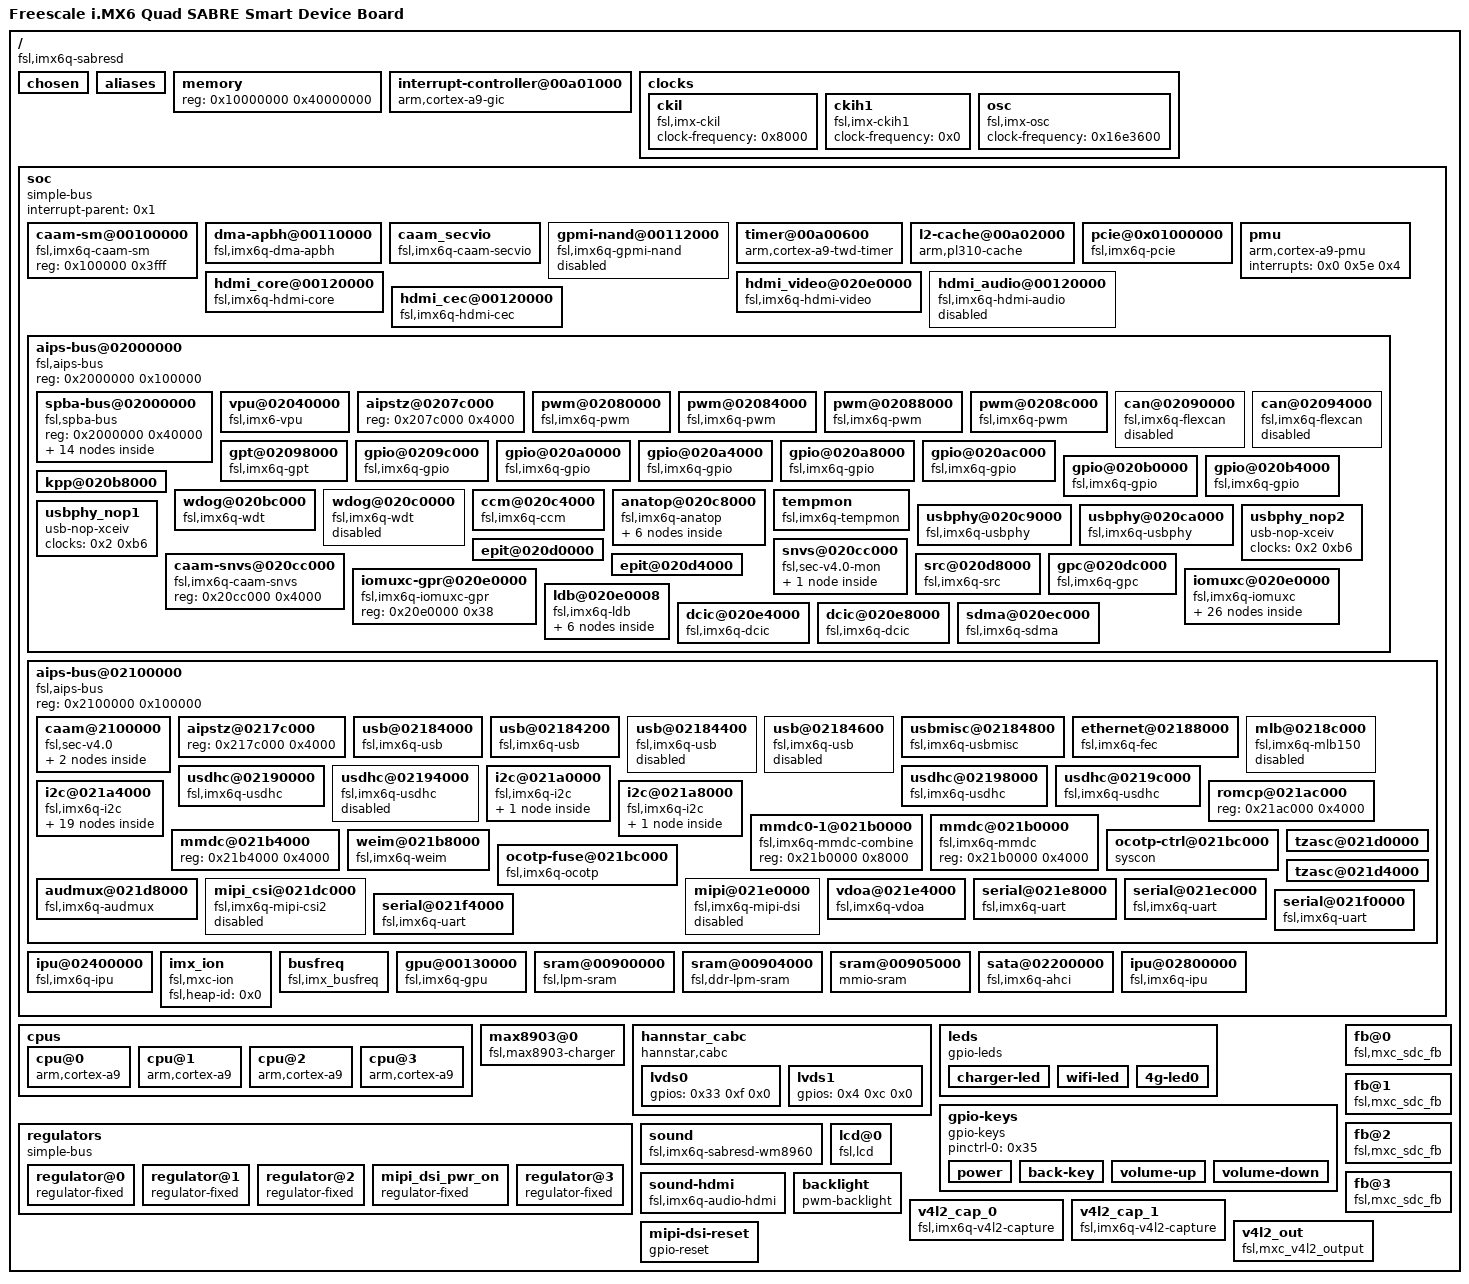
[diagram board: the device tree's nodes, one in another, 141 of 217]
/dts-v1/;

/ {
	#address-cells = <0x1>;
	#size-cells = <0x1>;
	model = "Freescale i.MX6 Quad SABRE Smart Device Board";
	compatible = "fsl,imx6q-sabresd", "fsl,imx6q";

	chosen {
	};

	aliases {
		gpio0 = "/soc/aips-bus@02000000/gpio@0209c000";
		gpio1 = "/soc/aips-bus@02000000/gpio@020a0000";
		gpio2 = "/soc/aips-bus@02000000/gpio@020a4000";
		gpio3 = "/soc/aips-bus@02000000/gpio@020a8000";
		gpio4 = "/soc/aips-bus@02000000/gpio@020ac000";
		gpio5 = "/soc/aips-bus@02000000/gpio@020b0000";
		gpio6 = "/soc/aips-bus@02000000/gpio@020b4000";
		i2c0 = "/soc/aips-bus@02100000/i2c@021a0000";
		i2c1 = "/soc/aips-bus@02100000/i2c@021a4000";
		i2c2 = "/soc/aips-bus@02100000/i2c@021a8000";
		ipu0 = "/soc/ipu@02400000";
		mmc0 = "/soc/aips-bus@02100000/usdhc@02190000";
		mmc1 = "/soc/aips-bus@02100000/usdhc@02194000";
		mmc2 = "/soc/aips-bus@02100000/usdhc@02198000";
		mmc3 = "/soc/aips-bus@02100000/usdhc@0219c000";
		serial0 = "/soc/aips-bus@02000000/spba-bus@02000000/serial@02020000";
		serial1 = "/soc/aips-bus@02100000/serial@021e8000";
		serial2 = "/soc/aips-bus@02100000/serial@021ec000";
		serial3 = "/soc/aips-bus@02100000/serial@021f0000";
		serial4 = "/soc/aips-bus@02100000/serial@021f4000";
		spi0 = "/soc/aips-bus@02000000/spba-bus@02000000/ecspi@02008000";
		spi1 = "/soc/aips-bus@02000000/spba-bus@02000000/ecspi@0200c000";
		spi2 = "/soc/aips-bus@02000000/spba-bus@02000000/ecspi@02010000";
		spi3 = "/soc/aips-bus@02000000/spba-bus@02000000/ecspi@02014000";
		usbphy0 = "/soc/aips-bus@02000000/usbphy@020c9000";
		usbphy1 = "/soc/aips-bus@02000000/usbphy@020ca000";
		ipu1 = "/soc/ipu@02800000";
		mxcfb0 = "/fb@0";
		mxcfb1 = "/fb@1";
		mxcfb2 = "/fb@2";
		mxcfb3 = "/fb@3";
	};

	memory {
		device_type = "memory";
		reg = <0x10000000 0x40000000>;
	};

	interrupt-controller@00a01000 {
		compatible = "arm,cortex-a9-gic";
		#interrupt-cells = <0x3>;
		#address-cells = <0x1>;
		#size-cells = <0x1>;
		interrupt-controller;
		reg = <0xa01000 0x1000 0xa00100 0x100>;
		linux,phandle = <0x1>;
		phandle = <0x1>;
	};

	clocks {
		#address-cells = <0x1>;
		#size-cells = <0x0>;

		ckil {
			compatible = "fsl,imx-ckil", "fixed-clock";
			clock-frequency = <0x8000>;
		};

		ckih1 {
			compatible = "fsl,imx-ckih1", "fixed-clock";
			clock-frequency = <0x0>;
		};

		osc {
			compatible = "fsl,imx-osc", "fixed-clock";
			clock-frequency = <0x16e3600>;
		};
	};

	soc {
		#address-cells = <0x1>;
		#size-cells = <0x1>;
		compatible = "simple-bus";
		interrupt-parent = <0x1>;
		ranges;

		caam-sm@00100000 {
			compatible = "fsl,imx6q-caam-sm";
			reg = <0x100000 0x3fff>;
		};

		dma-apbh@00110000 {
			compatible = "fsl,imx6q-dma-apbh", "fsl,imx28-dma-apbh";
			reg = <0x110000 0x2000>;
			interrupts = <0x0 0xd 0x4 0x0 0xd 0x4 0x0 0xd 0x4 0x0 0xd 0x4>;
			interrupt-names = "gpmi0", "gpmi1", "gpmi2", "gpmi3";
			#dma-cells = <0x1>;
			dma-channels = <0x4>;
			clocks = <0x2 0x6a>;
			linux,phandle = <0x3>;
			phandle = <0x3>;
		};

		caam_secvio {
			compatible = "fsl,imx6q-caam-secvio";
			interrupts = <0x0 0x14 0x4>;
			secvio_src = <0x8000001d>;
		};

		gpmi-nand@00112000 {
			compatible = "fsl,imx6q-gpmi-nand";
			#address-cells = <0x1>;
			#size-cells = <0x1>;
			reg = <0x112000 0x2000 0x114000 0x2000>;
			reg-names = "gpmi-nand", "bch";
			interrupts = <0x0 0xf 0x4>;
			interrupt-names = "bch";
			clocks = <0x2 0x98 0x2 0x99 0x2 0x97 0x2 0x96 0x2 0x95>;
			clock-names = "gpmi_io", "gpmi_apb", "gpmi_bch", "gpmi_bch_apb", "per1_bch";
			dmas = <0x3 0x0>;
			dma-names = "rx-tx";
			status = "disabled";
		};

		timer@00a00600 {
			compatible = "arm,cortex-a9-twd-timer";
			reg = <0xa00600 0x20>;
			interrupts = <0x1 0xd 0xf01>;
			clocks = <0x2 0xf>;
		};

		l2-cache@00a02000 {
			compatible = "arm,pl310-cache";
			reg = <0xa02000 0x1000>;
			interrupts = <0x0 0x5c 0x4>;
			cache-unified;
			cache-level = <0x2>;
			arm,tag-latency = <0x4 0x2 0x3>;
			arm,data-latency = <0x4 0x2 0x3>;
			linux,phandle = <0x30>;
			phandle = <0x30>;
		};

		pcie@0x01000000 {
			compatible = "fsl,imx6q-pcie", "snps,dw-pcie";
			reg = <0x1ffc000 0x4000 0x1f00000 0x80000>;
			reg-names = "dbi", "config";
			#address-cells = <0x3>;
			#size-cells = <0x2>;
			device_type = "pci";
			ranges = <0x81000000 0x0 0x0 0x1f80000 0x0 0x10000 0x82000000 0x0 0x1000000 0x1000000 0x0 0xf00000>;
			num-lanes = <0x1>;
			interrupts = <0x0 0x78 0x4>;
			interrupt-names = "msi";
			#interrupt-cells = <0x1>;
			interrupt-map-mask = <0x0 0x0 0x0 0x7>;
			interrupt-map = <0x0 0x0 0x0 0x1 0x1 0x0 0x7b 0x4 0x0 0x0 0x0 0x2 0x1 0x0 0x7a 0x4 0x0 0x0 0x0 0x3 0x1 0x0 0x79 0x4 0x0 0x0 0x0 0x4 0x1 0x0 0x78 0x4>;
			clocks = <0x2 0xbd 0x2 0xbb 0x2 0xce 0x2 0x90>;
			clock-names = "pcie_phy", "ref_100m", "pcie_bus", "pcie";
			status = "okay";
			power-on-gpio = <0x4 0x4 0x0>;
			reset-gpio = <0x4 0xc 0x0>;
		};

		pmu {
			compatible = "arm,cortex-a9-pmu";
			interrupts = <0x0 0x5e 0x4>;
		};

		hdmi_core@00120000 {
			compatible = "fsl,imx6q-hdmi-core";
			reg = <0x120000 0x9000>;
			clocks = <0x2 0x7c 0x2 0x7b 0x2 0x8a>;
			clock-names = "hdmi_isfr", "hdmi_iahb", "mipi_core";
			status = "okay";
			ipu_id = <0x0>;
			disp_id = <0x1>;
		};

		hdmi_video@020e0000 {
			compatible = "fsl,imx6q-hdmi-video";
			reg = <0x20e0000 0x1000>;
			reg-names = "hdmi_gpr";
			interrupts = <0x0 0x73 0x4>;
			clocks = <0x2 0x7c 0x2 0x7b 0x2 0x8a>;
			clock-names = "hdmi_isfr", "hdmi_iahb", "mipi_core";
			status = "okay";
			fsl,phy_reg_vlev = <0x294>;
			fsl,phy_reg_cksymtx = <0x800d>;
		};

		hdmi_audio@00120000 {
			compatible = "fsl,imx6q-hdmi-audio";
			clocks = <0x2 0x7c 0x2 0x7b 0x2 0x8a>;
			clock-names = "hdmi_isfr", "hdmi_iahb", "mipi_core";
			dmas = <0x5 0x2 0x18 0x0>;
			dma-names = "tx";
			status = "disabled";
			linux,phandle = <0x38>;
			phandle = <0x38>;
		};

		hdmi_cec@00120000 {
			compatible = "fsl,imx6q-hdmi-cec";
			interrupts = <0x0 0x73 0x4>;
			status = "okay";
			pinctrl-names = "default";
			pinctrl-0 = <0x6>;
		};

		aips-bus@02000000 {
			compatible = "fsl,aips-bus", "simple-bus";
			#address-cells = <0x1>;
			#size-cells = <0x1>;
			reg = <0x2000000 0x100000>;
			ranges;

			spba-bus@02000000 {
				compatible = "fsl,spba-bus", "simple-bus";
				#address-cells = <0x1>;
				#size-cells = <0x1>;
				reg = <0x2000000 0x40000>;
				ranges;

				spdif@02004000 {
					compatible = "fsl,imx35-spdif";
					reg = <0x2004000 0x4000>;
					interrupts = <0x0 0x34 0x4>;
					dmas = <0x5 0xe 0x12 0x0 0x5 0xf 0x12 0x0>;
					dma-names = "rx", "tx";
					clocks = <0x2 0xf9 0x2 0x3 0x2 0xc5 0x2 0x6b 0x2 0x0 0x2 0x76 0x2 0x3e 0x2 0x8b 0x2 0x0 0x2 0x9c>;
					clock-names = "core", "rxtx0", "rxtx1", "rxtx2", "rxtx3", "rxtx4", "rxtx5", "rxtx6", "rxtx7", "dma";
					status = "disabled";
				};

				ecspi@02008000 {
					#address-cells = <0x1>;
					#size-cells = <0x0>;
					compatible = "fsl,imx6q-ecspi", "fsl,imx51-ecspi";
					reg = <0x2008000 0x4000>;
					interrupts = <0x0 0x1f 0x4>;
					clocks = <0x2 0x70 0x2 0x70>;
					clock-names = "ipg", "per";
					status = "okay";
					dmas = <0x5 0x3 0x7 0x1 0x5 0x4 0x7 0x2>;
					dma-names = "rx", "tx";
					fsl,spi-num-chipselects = <0x1>;
					cs-gpios = <0x7 0x9 0x0>;
					pinctrl-names = "default";
					pinctrl-0 = <0x8>;

					m25p80@0 {
						#address-cells = <0x1>;
						#size-cells = <0x1>;
						compatible = "st,m25p32";
						spi-max-frequency = <0x1312d00>;
						reg = <0x0>;
					};
				};

				ecspi@0200c000 {
					#address-cells = <0x1>;
					#size-cells = <0x0>;
					compatible = "fsl,imx6q-ecspi", "fsl,imx51-ecspi";
					reg = <0x200c000 0x4000>;
					interrupts = <0x0 0x20 0x4>;
					clocks = <0x2 0x71 0x2 0x71>;
					clock-names = "ipg", "per";
					status = "disabled";
					dmas = <0x5 0x5 0x7 0x1 0x5 0x6 0x7 0x2>;
					dma-names = "rx", "tx";
				};

				ecspi@02010000 {
					#address-cells = <0x1>;
					#size-cells = <0x0>;
					compatible = "fsl,imx6q-ecspi", "fsl,imx51-ecspi";
					reg = <0x2010000 0x4000>;
					interrupts = <0x0 0x21 0x4>;
					clocks = <0x2 0x72 0x2 0x72>;
					clock-names = "ipg", "per";
					status = "disabled";
					dmas = <0x5 0x7 0x7 0x1 0x5 0x8 0x7 0x2>;
					dma-names = "rx", "tx";
				};

				ecspi@02014000 {
					#address-cells = <0x1>;
					#size-cells = <0x0>;
					compatible = "fsl,imx6q-ecspi", "fsl,imx51-ecspi";
					reg = <0x2014000 0x4000>;
					interrupts = <0x0 0x22 0x4>;
					clocks = <0x2 0x73 0x2 0x73>;
					clock-names = "ipg", "per";
					status = "disabled";
					dmas = <0x5 0x9 0x7 0x1 0x5 0xa 0x7 0x2>;
					dma-names = "rx", "tx";
				};

				serial@02020000 {
					compatible = "fsl,imx6q-uart", "fsl,imx21-uart";
					reg = <0x2020000 0x4000>;
					interrupts = <0x0 0x1a 0x4>;
					clocks = <0x2 0xa0 0x2 0xa1>;
					clock-names = "ipg", "per";
					dmas = <0x5 0x19 0x4 0x0 0x5 0x1a 0x4 0x0>;
					dma-names = "rx", "tx";
					status = "okay";
					pinctrl-names = "default";
					pinctrl-0 = <0x9>;
				};

				esai@02024000 {
					compatible = "fsl,imx35-esai";
					reg = <0x2024000 0x4000>;
					interrupts = <0x0 0x33 0x4>;
					clocks = <0x2 0xd9 0x2 0xd0 0x2 0x76 0x2 0xd9 0x2 0x9c>;
					clock-names = "core", "mem", "extal", "fsys", "dma";
					dmas = <0x5 0x17 0x15 0x0 0x5 0x18 0x15 0x0>;
					dma-names = "rx", "tx";
					status = "disabled";
				};

				ssi@02028000 {
					compatible = "fsl,imx6q-ssi", "fsl,imx21-ssi";
					reg = <0x2028000 0x4000>;
					interrupts = <0x0 0x2e 0x4>;
					clocks = <0x2 0xb2 0x2 0x9d>;
					clock-names = "ipg", "baud";
					dmas = <0x5 0x25 0x16 0x0 0x5 0x26 0x16 0x0>;
					dma-names = "rx", "tx";
					fsl,fifo-depth = <0xf>;
					fsl,ssi-dma-events = <0x26 0x25>;
					status = "disabled";
				};

				ssi@0202c000 {
					compatible = "fsl,imx6q-ssi", "fsl,imx21-ssi";
					reg = <0x202c000 0x4000>;
					interrupts = <0x0 0x2f 0x4>;
					clocks = <0x2 0xb3 0x2 0x9e>;
					clock-names = "ipg", "baud";
					dmas = <0x5 0x29 0x16 0x0 0x5 0x2a 0x16 0x0>;
					dma-names = "rx", "tx";
					fsl,fifo-depth = <0xf>;
					fsl,ssi-dma-events = <0x2a 0x29>;
					status = "okay";
					fsl,mode = "i2s-slave";
					linux,phandle = <0x36>;
					phandle = <0x36>;
				};

				ssi@02030000 {
					compatible = "fsl,imx6q-ssi", "fsl,imx21-ssi";
					reg = <0x2030000 0x4000>;
					interrupts = <0x0 0x30 0x4>;
					clocks = <0x2 0xb4 0x2 0x9f>;
					clock-names = "ipg", "baud";
					dmas = <0x5 0x2d 0x16 0x0 0x5 0x2e 0x16 0x0>;
					dma-names = "rx", "tx";
					fsl,fifo-depth = <0xf>;
					fsl,ssi-dma-events = <0x2e 0x2d>;
					status = "disabled";
				};

				asrc@02034000 {
					compatible = "fsl,imx53-asrc";
					reg = <0x2034000 0x4000>;
					interrupts = <0x0 0x32 0x4>;
					clocks = <0x2 0xda 0x2 0xdb 0x2 0x0 0x2 0x0 0x2 0x0 0x2 0x0 0x2 0x0 0x2 0x0 0x2 0x0 0x2 0x0 0x2 0x0 0x2 0x0 0x2 0x0 0x2 0x0 0x2 0x0 0x2 0x6b 0x2 0x0 0x2 0x0 0x2 0x9c>;
					clock-names = "mem", "ipg", "asrck_0", "asrck_1", "asrck_2", "asrck_3", "asrck_4", "asrck_5", "asrck_6", "asrck_7", "asrck_8", "asrck_9", "asrck_a", "asrck_b", "asrck_c", "asrck_d", "asrck_e", "asrck_f", "dma";
					dmas = <0x5 0x11 0x17 0x1 0x5 0x12 0x17 0x1 0x5 0x13 0x17 0x1 0x5 0x14 0x17 0x1 0x5 0x15 0x17 0x1 0x5 0x16 0x17 0x1>;
					dma-names = "rxa", "rxb", "rxc", "txa", "txb", "txc";
					fsl,asrc-rate = <0xbb80>;
					fsl,asrc-width = <0x10>;
					status = "okay";
				};

				spba@0203c000 {
					reg = <0x203c000 0x4000>;
				};

				ecspi@02018000 {
					#address-cells = <0x1>;
					#size-cells = <0x0>;
					compatible = "fsl,imx6q-ecspi", "fsl,imx51-ecspi";
					reg = <0x2018000 0x4000>;
					interrupts = <0x0 0x23 0x4>;
					clocks = <0x2 0x74 0x2 0x74>;
					clock-names = "ipg", "per";
					status = "disabled";
				};
			};

			vpu@02040000 {
				compatible = "fsl,imx6-vpu";
				reg = <0x2040000 0x3c000>;
				reg-names = "vpu_regs";
				interrupts = <0x0 0x3 0x1 0x0 0xc 0x4>;
				interrupt-names = "vpu_jpu_irq", "vpu_ipi_irq";
				clocks = <0x2 0xa8 0x2 0x8c 0x2 0x8e>;
				clock-names = "vpu_clk", "mmdc_ch0_axi", "ocram";
				iramsize = <0x21000>;
				iram = <0xa>;
				resets = <0xb 0x1>;
				power-domains = <0xc 0x1>;
			};

			aipstz@0207c000 {
				reg = <0x207c000 0x4000>;
			};

			pwm@02080000 {
				#pwm-cells = <0x2>;
				compatible = "fsl,imx6q-pwm", "fsl,imx27-pwm";
				reg = <0x2080000 0x4000>;
				interrupts = <0x0 0x53 0x4>;
				clocks = <0x2 0x3e 0x2 0x91>;
				clock-names = "ipg", "per";
				pinctrl-names = "default";
				pinctrl-0 = <0xd>;
				status = "okay";
				linux,phandle = <0x3a>;
				phandle = <0x3a>;
			};

			pwm@02084000 {
				#pwm-cells = <0x2>;
				compatible = "fsl,imx6q-pwm", "fsl,imx27-pwm";
				reg = <0x2084000 0x4000>;
				interrupts = <0x0 0x54 0x4>;
				clocks = <0x2 0x3e 0x2 0x92>;
				clock-names = "ipg", "per";
			};

			pwm@02088000 {
				#pwm-cells = <0x2>;
				compatible = "fsl,imx6q-pwm", "fsl,imx27-pwm";
				reg = <0x2088000 0x4000>;
				interrupts = <0x0 0x55 0x4>;
				clocks = <0x2 0x3e 0x2 0x93>;
				clock-names = "ipg", "per";
			};

			pwm@0208c000 {
				#pwm-cells = <0x2>;
				compatible = "fsl,imx6q-pwm", "fsl,imx27-pwm";
				reg = <0x208c000 0x4000>;
				interrupts = <0x0 0x56 0x4>;
				clocks = <0x2 0x3e 0x2 0x94>;
				clock-names = "ipg", "per";
			};

			can@02090000 {
				compatible = "fsl,imx6q-flexcan";
				reg = <0x2090000 0x4000>;
				interrupts = <0x0 0x6e 0x4>;
				clocks = <0x2 0x6c 0x2 0x6d>;
				clock-names = "ipg", "per";
				stop-mode = <0xe 0x34 0x1c 0x10 0x11>;
				status = "disabled";
			};

			can@02094000 {
				compatible = "fsl,imx6q-flexcan";
				reg = <0x2094000 0x4000>;
				interrupts = <0x0 0x6f 0x4>;
				clocks = <0x2 0x6e 0x2 0x6f>;
				clock-names = "ipg", "per";
				stop-mode = <0xe 0x34 0x1d 0x10 0x12>;
				status = "disabled";
			};

			gpt@02098000 {
				compatible = "fsl,imx6q-gpt", "fsl,imx31-gpt";
				reg = <0x2098000 0x4000>;
				interrupts = <0x0 0x37 0x4>;
				clocks = <0x2 0x77 0x2 0x78>;
				clock-names = "ipg", "per";
			};

			gpio@0209c000 {
				compatible = "fsl,imx6q-gpio", "fsl,imx35-gpio";
				reg = <0x209c000 0x4000>;
				interrupts = <0x0 0x42 0x4 0x0 0x43 0x4>;
				gpio-controller;
				#gpio-cells = <0x2>;
				interrupt-controller;
				#interrupt-cells = <0x2>;
				linux,phandle = <0x34>;
				phandle = <0x34>;
			};

			gpio@020a0000 {
				compatible = "fsl,imx6q-gpio", "fsl,imx35-gpio";
				reg = <0x20a0000 0x4000>;
				interrupts = <0x0 0x44 0x4 0x0 0x45 0x4>;
				gpio-controller;
				#gpio-cells = <0x2>;
				interrupt-controller;
				#interrupt-cells = <0x2>;
				linux,phandle = <0x22>;
				phandle = <0x22>;
			};

			gpio@020a4000 {
				compatible = "fsl,imx6q-gpio", "fsl,imx35-gpio";
				reg = <0x20a4000 0x4000>;
				interrupts = <0x0 0x46 0x4 0x0 0x47 0x4>;
				gpio-controller;
				#gpio-cells = <0x2>;
				interrupt-controller;
				#interrupt-cells = <0x2>;
				linux,phandle = <0x27>;
				phandle = <0x27>;
			};

			gpio@020a8000 {
				compatible = "fsl,imx6q-gpio", "fsl,imx35-gpio";
				reg = <0x20a8000 0x4000>;
				interrupts = <0x0 0x48 0x4 0x0 0x49 0x4>;
				gpio-controller;
				#gpio-cells = <0x2>;
				interrupt-controller;
				#interrupt-cells = <0x2>;
				linux,phandle = <0x7>;
				phandle = <0x7>;
			};

			gpio@020ac000 {
				compatible = "fsl,imx6q-gpio", "fsl,imx35-gpio";
				reg = <0x20ac000 0x4000>;
				interrupts = <0x0 0x4a 0x4 0x0 0x4b 0x4>;
				gpio-controller;
				#gpio-cells = <0x2>;
				interrupt-controller;
				#interrupt-cells = <0x2>;
				linux,phandle = <0x1f>;
				phandle = <0x1f>;
			};

			gpio@020b0000 {
				compatible = "fsl,imx6q-gpio", "fsl,imx35-gpio";
				reg = <0x20b0000 0x4000>;
				interrupts = <0x0 0x4c 0x4 0x0 0x4d 0x4>;
				gpio-controller;
				#gpio-cells = <0x2>;
				interrupt-controller;
				#interrupt-cells = <0x2>;
				linux,phandle = <0x33>;
				phandle = <0x33>;
			};

			gpio@020b4000 {
				compatible = "fsl,imx6q-gpio", "fsl,imx35-gpio";
				reg = <0x20b4000 0x4000>;
				interrupts = <0x0 0x4e 0x4 0x0 0x4f 0x4>;
				gpio-controller;
				#gpio-cells = <0x2>;
				interrupt-controller;
				#interrupt-cells = <0x2>;
				linux,phandle = <0x4>;
				phandle = <0x4>;
			};

			kpp@020b8000 {
				reg = <0x20b8000 0x4000>;
				interrupts = <0x0 0x52 0x4>;
			};

			wdog@020bc000 {
				compatible = "fsl,imx6q-wdt", "fsl,imx21-wdt";
				reg = <0x20bc000 0x4000>;
				interrupts = <0x0 0x50 0x4>;
				clocks = <0x2 0x0>;
				status = "okay";
			};

			wdog@020c0000 {
				compatible = "fsl,imx6q-wdt", "fsl,imx21-wdt";
				reg = <0x20c0000 0x4000>;
				interrupts = <0x0 0x51 0x4>;
				clocks = <0x2 0x0>;
				status = "disabled";
			};

			ccm@020c4000 {
				compatible = "fsl,imx6q-ccm";
				reg = <0x20c4000 0x4000>;
				interrupts = <0x0 0x57 0x4 0x0 0x58 0x4>;
				#clock-cells = <0x1>;
				fsl,ldb-di0-parent = <0x2 0x4>;
				fsl,ldb-di1-parent = <0x2 0x4>;
				linux,phandle = <0x2>;
				phandle = <0x2>;
			};

			anatop@020c8000 {
				compatible = "fsl,imx6q-anatop", "syscon", "simple-bus";
				reg = <0x20c8000 0x1000>;
				interrupts = <0x0 0x31 0x4 0x0 0x36 0x4 0x0 0x7f 0x4>;
				linux,phandle = <0xf>;
				phandle = <0xf>;

				regulator-1p1@110 {
					compatible = "fsl,anatop-regulator";
					regulator-name = "vdd1p1";
					regulator-min-microvolt = <0xc3500>;
					regulator-max-microvolt = <0x14fb18>;
					regulator-always-on;
					anatop-reg-offset = <0x110>;
					anatop-vol-bit-shift = <0x8>;
					anatop-vol-bit-width = <0x5>;
					anatop-min-bit-val = <0x4>;
					anatop-min-voltage = <0xc3500>;
					anatop-max-voltage = <0x14fb18>;
					anatop-enable-bit = <0x0>;
				};

				regulator-3p0@120 {
					compatible = "fsl,anatop-regulator";
					regulator-name = "vdd3p0";
					regulator-min-microvolt = <0x280de8>;
					regulator-max-microvolt = <0x33e140>;
					anatop-reg-offset = <0x120>;
					anatop-vol-bit-shift = <0x8>;
					anatop-vol-bit-width = <0x5>;
					anatop-min-bit-val = <0x0>;
					anatop-min-voltage = <0x280de8>;
					anatop-max-voltage = <0x33e140>;
					anatop-enable-bit = <0x0>;
					linux,phandle = <0x11>;
					phandle = <0x11>;
				};

				regulator-2p5@130 {
					compatible = "fsl,anatop-regulator";
					regulator-name = "vdd2p5";
					regulator-min-microvolt = <0x1e8480>;
					regulator-max-microvolt = <0x29f630>;
					regulator-always-on;
					anatop-reg-offset = <0x130>;
					anatop-vol-bit-shift = <0x8>;
					anatop-vol-bit-width = <0x5>;
					anatop-min-bit-val = <0x0>;
					anatop-min-voltage = <0x1e8480>;
					anatop-max-voltage = <0x29f630>;
					anatop-enable-bit = <0x0>;
				};

				regulator-vddcore@140 {
					compatible = "fsl,anatop-regulator";
					regulator-name = "vddarm";
					regulator-min-microvolt = <0xb1008>;
					regulator-max-microvolt = <0x162010>;
					regulator-always-on;
					anatop-reg-offset = <0x140>;
					anatop-vol-bit-shift = <0x0>;
					anatop-vol-bit-width = <0x5>;
					anatop-delay-reg-offset = <0x170>;
					anatop-delay-bit-shift = <0x18>;
					anatop-delay-bit-width = <0x2>;
					anatop-min-bit-val = <0x1>;
					anatop-min-voltage = <0xb1008>;
					anatop-max-voltage = <0x162010>;
					regulator-allow-bypass;
					linux,phandle = <0x31>;
					phandle = <0x31>;
				};

				regulator-vddpu@140 {
					compatible = "fsl,anatop-regulator";
					regulator-name = "vddpu";
					regulator-min-microvolt = <0xb1008>;
					regulator-max-microvolt = <0x162010>;
					regulator-enable-ramp-delay = <0x96>;
					regulator-boot-on;
					anatop-reg-offset = <0x140>;
					anatop-vol-bit-shift = <0x9>;
					anatop-vol-bit-width = <0x5>;
					anatop-delay-reg-offset = <0x170>;
					anatop-delay-bit-shift = <0x1a>;
					anatop-delay-bit-width = <0x2>;
					anatop-min-bit-val = <0x1>;
					anatop-min-voltage = <0xb1008>;
					anatop-max-voltage = <0x162010>;
					regulator-allow-bypass;
					linux,phandle = <0x12>;
					phandle = <0x12>;
				};

				regulator-vddsoc@140 {
					compatible = "fsl,anatop-regulator";
					regulator-name = "vddsoc";
					regulator-min-microvolt = <0xb1008>;
					regulator-max-microvolt = <0x162010>;
					regulator-always-on;
					anatop-reg-offset = <0x140>;
					anatop-vol-bit-shift = <0x12>;
					anatop-vol-bit-width = <0x5>;
					anatop-delay-reg-offset = <0x170>;
					anatop-delay-bit-shift = <0x1c>;
					anatop-delay-bit-width = <0x2>;
					anatop-min-bit-val = <0x1>;
					anatop-min-voltage = <0xb1008>;
					anatop-max-voltage = <0x162010>;
					regulator-allow-bypass;
					linux,phandle = <0x32>;
					phandle = <0x32>;
				};
			};

			tempmon {
				compatible = "fsl,imx6q-tempmon";
				interrupts = <0x0 0x31 0x4>;
				fsl,tempmon = <0xf>;
				fsl,tempmon-data = <0x10>;
				clocks = <0x2 0xac>;
			};

			usbphy@020c9000 {
				compatible = "fsl,imx6q-usbphy", "fsl,imx23-usbphy";
				reg = <0x20c9000 0x1000>;
				interrupts = <0x0 0x2c 0x4>;
				clocks = <0x2 0xb6>;
				phy-3p0-supply = <0x11>;
				fsl,anatop = <0xf>;
				linux,phandle = <0x16>;
				phandle = <0x16>;
			};

			usbphy@020ca000 {
				compatible = "fsl,imx6q-usbphy", "fsl,imx23-usbphy";
				reg = <0x20ca000 0x1000>;
				interrupts = <0x0 0x2d 0x4>;
				clocks = <0x2 0xb7>;
				phy-3p0-supply = <0x11>;
				fsl,anatop = <0xf>;
				linux,phandle = <0x1a>;
				phandle = <0x1a>;
			};

			usbphy_nop1 {
				compatible = "usb-nop-xceiv";
				clocks = <0x2 0xb6>;
				clock-names = "main_clk";
				linux,phandle = <0x1c>;
				phandle = <0x1c>;
			};

			usbphy_nop2 {
				compatible = "usb-nop-xceiv";
				clocks = <0x2 0xb6>;
				clock-names = "main_clk";
				linux,phandle = <0x1d>;
				phandle = <0x1d>;
			};

			caam-snvs@020cc000 {
				compatible = "fsl,imx6q-caam-snvs";
				reg = <0x20cc000 0x4000>;
			};

			snvs@020cc000 {
				compatible = "fsl,sec-v4.0-mon", "simple-bus";
				#address-cells = <0x1>;
				#size-cells = <0x1>;
				ranges = <0x0 0x20cc000 0x4000>;

				snvs-rtc-lp@34 {
					compatible = "fsl,sec-v4.0-mon-rtc-lp";
					reg = <0x34 0x58>;
					interrupts = <0x0 0x13 0x4 0x0 0x14 0x4>;
				};
			};

			epit@020d0000 {
				reg = <0x20d0000 0x4000>;
				interrupts = <0x0 0x38 0x4>;
			};

			epit@020d4000 {
				reg = <0x20d4000 0x4000>;
				interrupts = <0x0 0x39 0x4>;
			};

			src@020d8000 {
				compatible = "fsl,imx6q-src", "fsl,imx51-src";
				reg = <0x20d8000 0x4000>;
				interrupts = <0x0 0x5b 0x4 0x0 0x60 0x4>;
				#reset-cells = <0x1>;
				linux,phandle = <0xb>;
				phandle = <0xb>;
			};

			gpc@020dc000 {
				compatible = "fsl,imx6q-gpc";
				reg = <0x20dc000 0x4000>;
				interrupts = <0x0 0x59 0x4 0x0 0x5a 0x4>;
				pu-supply = <0x12>;
				clocks = <0x2 0x7a 0x2 0x4a 0x2 0x79 0x2 0x1a 0x2 0x8f 0x2 0xa8 0x2 0x3e>;
				#power-domain-cells = <0x1>;
				fsl,ldo-bypass = <0x0>;
				fsl,wdog-reset = <0x1>;
				linux,phandle = <0xc>;
				phandle = <0xc>;
			};

			iomuxc-gpr@020e0000 {
				compatible = "fsl,imx6q-iomuxc-gpr", "syscon";
				reg = <0x20e0000 0x38>;
				linux,phandle = <0xe>;
				phandle = <0xe>;
			};

			iomuxc@020e0000 {
				compatible = "fsl,imx6q-iomuxc";
				reg = <0x20e0000 0x4000>;
				pinctrl-names = "default";
				pinctrl-0 = <0x13>;

				ipu2 {

					ipu2grp-1 {
						fsl,pins = <0x15c 0x470 0x0 0x1 0x0 0x10 0x160 0x474 0x0 0x1 0x0 0x10 0x164 0x478 0x0 0x1 0x0 0x10 0x168 0x47c 0x0 0x1 0x0 0x10 0x16c 0x480 0x0 0x1 0x0 0x80000000 0x170 0x484 0x0 0x1 0x0 0x10 0x174 0x488 0x0 0x1 0x0 0x10 0x178 0x48c 0x0 0x1 0x0 0x10 0x17c 0x490 0x0 0x1 0x0 0x10 0x180 0x494 0x0 0x1 0x0 0x10 0x184 0x498 0x0 0x1 0x0 0x10 0x188 0x49c 0x0 0x1 0x0 0x10 0x18c 0x4a0 0x0 0x1 0x0 0x10 0x190 0x4a4 0x0 0x1 0x0 0x10 0x194 0x4a8 0x0 0x1 0x0 0x10 0x198 0x4ac 0x0 0x1 0x0 0x10 0x19c 0x4b0 0x0 0x1 0x0 0x10 0x1a0 0x4b4 0x0 0x1 0x0 0x10 0x1a4 0x4b8 0x0 0x1 0x0 0x10 0x1a8 0x4bc 0x0 0x1 0x0 0x10 0x1ac 0x4c0 0x0 0x1 0x0 0x10 0x1b0 0x4c4 0x0 0x1 0x0 0x10 0x1b4 0x4c8 0x0 0x1 0x0 0x10 0x1b8 0x4cc 0x0 0x1 0x0 0x10 0x1bc 0x4d0 0x0 0x1 0x0 0x10 0x1c0 0x4d4 0x0 0x1 0x0 0x10 0x1c4 0x4d8 0x0 0x1 0x0 0x10 0x1c8 0x4dc 0x0 0x1 0x0 0x10 0x1cc 0x4e0 0x0 0x1 0x0 0x10>;
					};
				};

				imx6qdl-sabresd {

					hoggrp {
						fsl,pins = <0x2fc 0x6e4 0x0 0x5 0x0 0x80000000 0x300 0x6e8 0x0 0x5 0x0 0x80000000 0x304 0x6ec 0x0 0x5 0x0 0x80000000 0x308 0x6f0 0x0 0x5 0x0 0x80000000 0x220 0x5f0 0x0 0x0 0x0 0x130b0 0x2d4 0x6bc 0x0 0x5 0x0 0x80000000 0x2d8 0x6c0 0x0 0x5 0x0 0x80000000 0xa8 0x3bc 0x0 0x5 0x0 0x80000000 0xbc 0x3d0 0x0 0x5 0x0 0x80000000 0xfc 0x410 0x0 0x5 0x0 0x80000000 0x88 0x39c 0x0 0x5 0x0 0x80000000 0xac 0x3c0 0x0 0x5 0x0 0x80000000 0xb0 0x3c4 0x0 0x5 0x0 0x80000000 0x90 0x3a4 0x0 0x5 0x0 0x80000000 0x228 0x5f8 0x0 0x5 0x0 0x80000000 0x138 0x44c 0x0 0x5 0x0 0x80000000 0x224 0x5f4 0x0 0x1 0x0 0x80000000 0x2e4 0x6cc 0x0 0x5 0x0 0x80000000 0x2e8 0x6d0 0x0 0x5 0x0 0x80000000 0x2ec 0x6d4 0x0 0x5 0x0 0x80000000 0x2f0 0x6d8 0x0 0x5 0x0 0x80000000 0x208 0x5d8 0x0 0x5 0x0 0x80000000 0x224 0x5f4 0x0 0x4 0x0 0x80000000 0x2a0 0x670 0x0 0x5 0x0 0x80000000 0x24c 0x61c 0x0 0x5 0x0 0x80000000 0x2c0 0x6a8 0x0 0x5 0x0 0x80000000 0x1b4 0x4c8 0x0 0x5 0x0 0x80000000 0x278 0x648 0x0 0x5 0x0 0x80000000 0x27c 0x64c 0x0 0x5 0x0 0x80000000 0x280 0x650 0x0 0x5 0x0 0x80000000 0x284 0x654 0x0 0x5 0x0 0x80000000 0x290 0x660 0x0 0x5 0x0 0x80000000 0x294 0x664 0x0 0x5 0x0 0x80000000 0x298 0x668 0x0 0x5 0x0 0x80000000 0x29c 0x66c 0x0 0x5 0x0 0x80000000>;
						linux,phandle = <0x13>;
						phandle = <0x13>;
					};

					audmuxgrp {
						fsl,pins = <0x54 0x368 0x7b4 0x3 0x0 0x130b0 0x35c 0x744 0x7c4 0x3 0x1 0x130b0 0x50 0x364 0x7b8 0x3 0x0 0x110b0 0x4c 0x360 0x7c8 0x3 0x0 0x130b0>;
						linux,phandle = <0x29>;
						phandle = <0x29>;
					};

					ecspi1grp {
						fsl,pins = <0x200 0x5d0 0x7f8 0x0 0x2 0x100b1>;
						linux,phandle = <0x8>;
						phandle = <0x8>;
					};

					enetgrp {
						fsl,pins = <0x1c0 0x4d4 0x0 0x5 0x0 0x80000000 0x248 0x618 0x83c 0x2 0x1 0x4001b0a1 0x1f4 0x508 0x0 0x1 0x0 0x1b0a8 0x1d0 0x4e4 0x840 0x1 0x0 0x1b0a8 0x1dc 0x4f0 0x858 0x1 0x1 0x1b0a8 0x1d8 0x4ec 0x0 0x1 0x0 0x1b0a8 0x1e8 0x4fc 0x0 0x1 0x0 0x1b0a8 0x1e4 0x4f8 0x848 0x1 0x1 0x1b0a8 0x1e0 0x4f4 0x84c 0x1 0x1 0x1b0a8 0x1f0 0x504 0x0 0x1 0x0 0x1b0a8 0x1ec 0x500 0x0 0x1 0x0 0x1b0a8>;
						linux,phandle = <0x1e>;
						phandle = <0x1e>;
					};

					gpio_keysgrp {
						fsl,pins = <0x2d0 0x6b8 0x0 0x5 0x0 0x80000000 0x2cc 0x6b4 0x0 0x5 0x0 0x80000000>;
						linux,phandle = <0x35>;
						phandle = <0x35>;
					};

					hdmicecgrp {
						fsl,pins = <0x20c 0x5dc 0x88c 0x6 0x1 0x1f8b0>;
						linux,phandle = <0x6>;
						phandle = <0x6>;
					};

					hdmihdcpgrp {
						fsl,pins = <0x210 0x5e0 0x890 0x2 0x1 0x4001b8b1 0x214 0x5e4 0x894 0x2 0x1 0x4001b8b1>;
					};

					i2c1grp {
						fsl,pins = <0xa4 0x3b8 0x898 0x6 0x0 0x4001b8b1 0xc4 0x3d8 0x89c 0x1 0x0 0x4001b8b1>;
						linux,phandle = <0x24>;
						phandle = <0x24>;
					};

					i2c2grp {
						fsl,pins = <0x210 0x5e0 0x8a0 0x4 0x1 0x4001b8b1 0x214 0x5e4 0x8a4 0x4 0x1 0x4001b8b1>;
						linux,phandle = <0x26>;
						phandle = <0x26>;
					};

					i2c3grp {
						fsl,pins = <0x22c 0x5fc 0x8a8 0x2 0x1 0x4001b8b1 0x230 0x600 0x8ac 0x2 0x1 0x4001b8b1>;
						linux,phandle = <0x28>;
						phandle = <0x28>;
					};

					ipu1grp {
						fsl,pins = <0x15c 0x470 0x0 0x0 0x0 0x10 0x160 0x474 0x0 0x0 0x0 0x10 0x164 0x478 0x0 0x0 0x0 0x10 0x168 0x47c 0x0 0x0 0x0 0x10 0x16c 0x480 0x0 0x0 0x0 0x80000000 0x170 0x484 0x0 0x0 0x0 0x10 0x174 0x488 0x0 0x0 0x0 0x10 0x178 0x48c 0x0 0x0 0x0 0x10 0x17c 0x490 0x0 0x0 0x0 0x10 0x180 0x494 0x0 0x0 0x0 0x10 0x184 0x498 0x0 0x0 0x0 0x10 0x188 0x49c 0x0 0x0 0x0 0x10 0x18c 0x4a0 0x0 0x0 0x0 0x10 0x190 0x4a4 0x0 0x0 0x0 0x10 0x194 0x4a8 0x0 0x0 0x0 0x10 0x198 0x4ac 0x0 0x0 0x0 0x10 0x19c 0x4b0 0x0 0x0 0x0 0x10 0x1a0 0x4b4 0x0 0x0 0x0 0x10 0x1a4 0x4b8 0x0 0x0 0x0 0x10 0x1a8 0x4bc 0x0 0x0 0x0 0x10 0x1ac 0x4c0 0x0 0x0 0x0 0x10 0x1b0 0x4c4 0x0 0x0 0x0 0x10 0x1b8 0x4cc 0x0 0x0 0x0 0x10 0x1bc 0x4d0 0x0 0x0 0x0 0x10 0x1c4 0x4d8 0x0 0x0 0x0 0x10 0x1c8 0x4dc 0x0 0x0 0x0 0x10 0x1cc 0x4e0 0x0 0x0 0x0 0x10>;
						linux,phandle = <0x39>;
						phandle = <0x39>;
					};

					ipu1grp-2 {
						fsl,pins;
					};

					pwm1grp {
						fsl,pins;
						linux,phandle = <0xd>;
						phandle = <0xd>;
					};

					uart1grp {
						fsl,pins = <0x2ac 0x694 0x920 0x1 0x3 0x1b0b1 0x2a8 0x690 0x0 0x1 0x0 0x1b0b1>;
						linux,phandle = <0x9>;
						phandle = <0x9>;
					};

					uart2grp {
						fsl,pins = <0x2b8 0x6a0 0x0 0x1 0x0 0x1b0b1 0x2bc 0x6a4 0x924 0x1 0x3 0x1b0b1 0x2b4 0x69c 0x928 0x1 0x5 0x1b0b1 0x2b0 0x698 0x0 0x1 0x0 0x1b0b1>;
						linux,phandle = <0x2c>;
						phandle = <0x2c>;
					};

					uart3grp {
						fsl,pins = <0xb8 0x3cc 0x930 0x2 0x1 0x1b0b1 0xb4 0x3c8 0x0 0x2 0x0 0x1b0b1>;
						linux,phandle = <0x2d>;
						phandle = <0x2d>;
					};

					uart4grp {
						fsl,pins = <0x1f8 0x5c8 0x0 0x4 0x0 0x1b0b1 0x1fc 0x5cc 0x938 0x4 0x1 0x1b0b1>;
						linux,phandle = <0x2e>;
						phandle = <0x2e>;
					};

					uart5grp {
						fsl,pins = <0x200 0x5d0 0x0 0x4 0x0 0x1b0b1 0x204 0x5d4 0x940 0x4 0x1 0x1b0b1>;
						linux,phandle = <0x2f>;
						phandle = <0x2f>;
					};

					usbotggrp {
						fsl,pins = <0x224 0x5f4 0x4 0x3 0xff0d0101 0x17059>;
						linux,phandle = <0x19>;
						phandle = <0x19>;
					};

					usdhc1grp {
						fsl,pins = <0x348 0x730 0x0 0x0 0x0 0x17059 0x350 0x738 0x0 0x0 0x0 0x10059 0x340 0x728 0x0 0x0 0x0 0x17059 0x33c 0x724 0x0 0x0 0x0 0x17059 0x34c 0x734 0x0 0x0 0x0 0x17059 0x344 0x72c 0x0 0x0 0x0 0x17059>;
						linux,phandle = <0x20>;
						phandle = <0x20>;
					};

					usdhc2grp {
						fsl,pins;
					};

					usdhc3grp {
						fsl,pins = <0x2c4 0x6ac 0x0 0x0 0x0 0x17059 0x2b4 0x69c 0x0 0x0 0x0 0x17059 0x2b0 0x698 0x0 0x0 0x0 0x17059 0x2ac 0x694 0x0 0x0 0x0 0x17059 0x2a8 0x690 0x0 0x0 0x0 0x17059>;
						linux,phandle = <0x21>;
						phandle = <0x21>;
					};

					usdhc4grp {
						fsl,pins = <0x2f4 0x6dc 0x0 0x0 0x0 0x17059 0x2f8 0x6e0 0x0 0x0 0x0 0x10059 0x31c 0x704 0x0 0x1 0x0 0x17059 0x320 0x708 0x0 0x1 0x0 0x17059 0x324 0x70c 0x0 0x1 0x0 0x17059 0x328 0x710 0x0 0x1 0x0 0x17059 0x32c 0x714 0x0 0x1 0x0 0x17059 0x330 0x718 0x0 0x1 0x0 0x17059 0x334 0x71c 0x0 0x1 0x0 0x17059 0x338 0x720 0x0 0x1 0x0 0x17059>;
						linux,phandle = <0x23>;
						phandle = <0x23>;
					};
				};
			};

			ldb@020e0008 {
				#address-cells = <0x1>;
				#size-cells = <0x0>;
				gpr = <0xe>;
				status = "okay";
				compatible = "fsl,imx6q-ldb", "fsl,imx53-ldb";
				clocks = <0x2 0x87 0x2 0x88 0x2 0x27 0x2 0x28 0x2 0x29 0x2 0x2a 0x2 0xb8 0x2 0xb9 0x2 0xd1 0x2 0xd2 0x2 0xd3 0x2 0xd4>;
				clock-names = "ldb_di0", "ldb_di1", "di0_sel", "di1_sel", "di2_sel", "di3_sel", "ldb_di0_div_3_5", "ldb_di1_div_3_5", "ldb_di0_div_7", "ldb_di1_div_7", "ldb_di0_div_sel", "ldb_di1_div_sel";

				lvds-channel@0 {
					reg = <0x0>;
					status = "okay";
					fsl,data-mapping = "spwg";
					fsl,data-width = <0x18>;
					primary;
					crtc = "ipu2-di0";

					display-timings {
						native-mode = <0x14>;

						hsd100pxn1 {
							clock-frequency = <0x43ce660>;
							hactive = <0x500>;
							vactive = <0x320>;
							hback-porch = <0x4e>;
							hfront-porch = <0x4f>;
							vback-porch = <0xa>;
							vfront-porch = <0xa>;
							hsync-len = <0x3>;
							vsync-len = <0x3>;
							linux,phandle = <0x14>;
							phandle = <0x14>;
						};
					};
				};

				lvds-channel@1 {
					reg = <0x1>;
					status = "okay";
					fsl,data-mapping = "spwg";
					fsl,data-width = <0x12>;
					primary;
					crtc = "ipu2-di1";

					display-timings {
						native-mode = <0x15>;

						hsd100pxn1 {
							clock-frequency = <0x3dfd240>;
							hactive = <0x400>;
							vactive = <0x300>;
							hback-porch = <0xdc>;
							hfront-porch = <0x28>;
							vback-porch = <0x15>;
							vfront-porch = <0x7>;
							hsync-len = <0x3c>;
							vsync-len = <0xa>;
							linux,phandle = <0x15>;
							phandle = <0x15>;
						};
					};
				};
			};

			dcic@020e4000 {
				compatible = "fsl,imx6q-dcic";
				reg = <0x20e4000 0x4000>;
				interrupts = <0x0 0x7c 0x4>;
				clocks = <0x2 0xd6 0x2 0xd6>;
				clock-names = "dcic", "disp-axi";
				gpr = <0xe>;
				status = "okay";
				dcic_id = <0x0>;
				dcic_mux = "dcic-hdmi";
			};

			dcic@020e8000 {
				compatible = "fsl,imx6q-dcic";
				reg = <0x20e8000 0x4000>;
				interrupts = <0x0 0x7d 0x4>;
				clocks = <0x2 0xd7 0x2 0xd7>;
				clock-names = "dcic", "disp-axi";
				gpr = <0xe>;
				status = "okay";
				dcic_id = <0x1>;
				dcic_mux = "dcic-lvds1";
			};

			sdma@020ec000 {
				compatible = "fsl,imx6q-sdma", "fsl,imx35-sdma";
				reg = <0x20ec000 0x4000>;
				interrupts = <0x0 0x2 0x4>;
				clocks = <0x2 0x9b 0x2 0x9b>;
				clock-names = "ipg", "ahb";
				#dma-cells = <0x3>;
				fsl,sdma-ram-script-name = "imx/sdma/sdma-imx6q.bin";
				linux,phandle = <0x5>;
				phandle = <0x5>;
			};
		};

		aips-bus@02100000 {
			compatible = "fsl,aips-bus", "simple-bus";
			#address-cells = <0x1>;
			#size-cells = <0x1>;
			reg = <0x2100000 0x100000>;
			ranges;

			caam@2100000 {
				compatible = "fsl,sec-v4.0";
				#address-cells = <0x1>;
				#size-cells = <0x1>;
				reg = <0x2100000 0x40000>;
				ranges = <0x0 0x2100000 0x40000>;
				interrupt-parent = <0x1>;
				clocks = <0x2 0xf6 0x2 0xf7 0x2 0xf8 0x2 0xc4>;
				clock-names = "caam_mem", "caam_aclk", "caam_ipg", "caam_emi_slow";

				jr0@1000 {
					compatible = "fsl,sec-v4.0-job-ring";
					reg = <0x1000 0x1000>;
					interrupt-parent = <0x1>;
					interrupts = <0x0 0x69 0x4>;
				};

				jr1@2000 {
					compatible = "fsl,sec-v4.0-job-ring";
					reg = <0x2000 0x1000>;
					interrupt-parent = <0x1>;
					interrupts = <0x0 0x6a 0x4>;
				};
			};

			aipstz@0217c000 {
				reg = <0x217c000 0x4000>;
			};

			usb@02184000 {
				compatible = "fsl,imx6q-usb", "fsl,imx27-usb";
				reg = <0x2184000 0x200>;
				interrupts = <0x0 0x2b 0x4>;
				clocks = <0x2 0xa2>;
				fsl,usbphy = <0x16>;
				fsl,usbmisc = <0x17 0x0>;
				fsl,anatop = <0xf>;
				status = "okay";
				vbus-supply = <0x18>;
				pinctrl-names = "default";
				pinctrl-0 = <0x19>;
				disable-over-current;
				srp-disable;
				hnp-disable;
				adp-disable;
			};

			usb@02184200 {
				compatible = "fsl,imx6q-usb", "fsl,imx27-usb";
				reg = <0x2184200 0x200>;
				interrupts = <0x0 0x28 0x4>;
				clocks = <0x2 0xa2>;
				fsl,usbphy = <0x1a>;
				fsl,usbmisc = <0x17 0x1>;
				status = "okay";
				vbus-supply = <0x1b>;
			};

			usb@02184400 {
				compatible = "fsl,imx6q-usb", "fsl,imx27-usb";
				reg = <0x2184400 0x200>;
				interrupts = <0x0 0x29 0x4>;
				clocks = <0x2 0xa2>;
				fsl,usbmisc = <0x17 0x2>;
				phy_type = "hsic";
				fsl,usbphy = <0x1c>;
				fsl,anatop = <0xf>;
				status = "disabled";
			};

			usb@02184600 {
				compatible = "fsl,imx6q-usb", "fsl,imx27-usb";
				reg = <0x2184600 0x200>;
				interrupts = <0x0 0x2a 0x4>;
				clocks = <0x2 0xa2>;
				fsl,usbmisc = <0x17 0x3>;
				phy_type = "hsic";
				fsl,usbphy = <0x1d>;
				fsl,anatop = <0xf>;
				status = "disabled";
			};

			usbmisc@02184800 {
				#index-cells = <0x1>;
				compatible = "fsl,imx6q-usbmisc";
				reg = <0x2184800 0x200>;
				clocks = <0x2 0xa2>;
				linux,phandle = <0x17>;
				phandle = <0x17>;
			};

			ethernet@02188000 {
				compatible = "fsl,imx6q-fec";
				reg = <0x2188000 0x4000>;
				interrupts-extended = <0x1 0x0 0x76 0x4 0x1 0x0 0x77 0x4>;
				clocks = <0x2 0x75 0x2 0x75 0x2 0xbe>;
				clock-names = "ipg", "ahb", "ptp";
				status = "okay";
				pinctrl-names = "default";
				pinctrl-0 = <0x1e>;
				phy-mode = "rmii";
				phy-reset-gpios = <0x1f 0xe 0x0>;
				phy-reset-duration = <0x1>;
				fsl,magic-packet;
			};

			mlb@0218c000 {
				compatible = "fsl,imx6q-mlb150";
				reg = <0x218c000 0x4000>;
				interrupts = <0x0 0x35 0x4 0x0 0x75 0x4 0x0 0x7e 0x4>;
				clocks = <0x2 0x8b 0x2 0xaf>;
				clock-names = "mlb", "pll8_mlb";
				iram = <0xa>;
				status = "disabled";
			};

			usdhc@02190000 {
				compatible = "fsl,imx6q-usdhc";
				reg = <0x2190000 0x4000>;
				interrupts = <0x0 0x16 0x4>;
				clocks = <0x2 0xa3 0x2 0xa3 0x2 0xa3>;
				clock-names = "ipg", "ahb", "per";
				bus-width = <0x4>;
				status = "okay";
				pinctrl-names = "default";
				pinctrl-0 = <0x20>;
				cd-gpios = <0x4 0x6 0x0>;
				no-1-8-v;
				keep-power-in-suspend;
				enable-sdio-wakeup;
			};

			usdhc@02194000 {
				compatible = "fsl,imx6q-usdhc";
				reg = <0x2194000 0x4000>;
				interrupts = <0x0 0x17 0x4>;
				clocks = <0x2 0xa4 0x2 0xa4 0x2 0xa4>;
				clock-names = "ipg", "ahb", "per";
				bus-width = <0x4>;
				status = "disabled";
			};

			usdhc@02198000 {
				compatible = "fsl,imx6q-usdhc";
				reg = <0x2198000 0x4000>;
				interrupts = <0x0 0x18 0x4>;
				clocks = <0x2 0xa5 0x2 0xa5 0x2 0xa5>;
				clock-names = "ipg", "ahb", "per";
				bus-width = <0x8>;
				status = "okay";
				pinctrl-names = "default";
				pinctrl-0 = <0x21>;
				cd-gpios = <0x22 0x0 0x0>;
				wp-gpios = <0x22 0x1 0x0>;
				no-1-8-v;
				keep-power-in-suspend;
				enable-sdio-wakeup;
			};

			usdhc@0219c000 {
				compatible = "fsl,imx6q-usdhc";
				reg = <0x219c000 0x4000>;
				interrupts = <0x0 0x19 0x4>;
				clocks = <0x2 0xa6 0x2 0xa6 0x2 0xa6>;
				clock-names = "ipg", "ahb", "per";
				bus-width = <0x8>;
				status = "okay";
				pinctrl-names = "default";
				pinctrl-0 = <0x23>;
				non-removable;
				no-1-8-v;
				keep-power-in-suspend;
			};

			i2c@021a0000 {
				#address-cells = <0x1>;
				#size-cells = <0x0>;
				compatible = "fsl,imx6q-i2c", "fsl,imx21-i2c";
				reg = <0x21a0000 0x4000>;
				interrupts = <0x0 0x24 0x4>;
				clocks = <0x2 0x7d>;
				status = "okay";
				clock-frequency = <0x186a0>;
				pinctrl-names = "default";
				pinctrl-0 = <0x24>;

				wm8960@1a {
					compatible = "wlf,wm8960";
					reg = <0x1a>;
					clocks = <0x2 0xc9>;
					wlf,shared-lrclk;
					DCVDD-supply = <0x25>;
					DBVDD-supply = <0x25>;
					AVDD-supply = <0x25>;
					MICVDD-supply = <0x25>;
					SPKVDD1-supply = <0x25>;
					SPKVDD2-supply = <0x25>;
					linux,phandle = <0x37>;
					phandle = <0x37>;
				};
			};

			i2c@021a4000 {
				#address-cells = <0x1>;
				#size-cells = <0x0>;
				compatible = "fsl,imx6q-i2c", "fsl,imx21-i2c";
				reg = <0x21a4000 0x4000>;
				interrupts = <0x0 0x25 0x4>;
				clocks = <0x2 0x7e>;
				status = "okay";
				clock-frequency = <0x186a0>;
				pinctrl-names = "default";
				pinctrl-0 = <0x26>;

				edid@50 {
					compatible = "fsl,imx6-hdmi-i2c";
					reg = <0x50>;
				};

				max11801@48 {
					compatible = "maxim,max11801";
					reg = <0x48>;
					interrupt-parent = <0x27>;
					interrupts = <0x1a 0x2>;
					work-mode = <0x1>;
				};

				pfuze100@08 {
					compatible = "fsl,pfuze100";
					reg = <0x8>;

					regulators {

						sw1ab {
							regulator-min-microvolt = <0x493e0>;
							regulator-max-microvolt = <0x1c9c38>;
							regulator-boot-on;
							regulator-always-on;
							regulator-ramp-delay = <0x186a>;
						};

						sw1c {
							regulator-min-microvolt = <0x493e0>;
							regulator-max-microvolt = <0x1c9c38>;
							regulator-boot-on;
							regulator-always-on;
							regulator-ramp-delay = <0x186a>;
						};

						sw2 {
							regulator-min-microvolt = <0xc3500>;
							regulator-max-microvolt = <0x325aa0>;
							regulator-boot-on;
							regulator-always-on;
							regulator-ramp-delay = <0x186a>;
						};

						sw3a {
							regulator-min-microvolt = <0x61a80>;
							regulator-max-microvolt = <0x1e22d8>;
							regulator-boot-on;
							regulator-always-on;
						};

						sw3b {
							regulator-min-microvolt = <0x61a80>;
							regulator-max-microvolt = <0x1e22d8>;
							regulator-boot-on;
							regulator-always-on;
						};

						sw4 {
							regulator-min-microvolt = <0xc3500>;
							regulator-max-microvolt = <0x325aa0>;
						};

						swbst {
							regulator-min-microvolt = <0x4c4b40>;
							regulator-max-microvolt = <0x4e9530>;
						};

						vsnvs {
							regulator-min-microvolt = <0xf4240>;
							regulator-max-microvolt = <0x2dc6c0>;
							regulator-boot-on;
							regulator-always-on;
						};

						vrefddr {
							regulator-boot-on;
							regulator-always-on;
						};

						vgen1 {
							regulator-min-microvolt = <0xc3500>;
							regulator-max-microvolt = <0x17a6b0>;
						};

						vgen2 {
							regulator-min-microvolt = <0xc3500>;
							regulator-max-microvolt = <0x17a6b0>;
						};

						vgen3 {
							regulator-min-microvolt = <0x1b7740>;
							regulator-max-microvolt = <0x325aa0>;
						};

						vgen4 {
							regulator-min-microvolt = <0x1b7740>;
							regulator-max-microvolt = <0x325aa0>;
							regulator-always-on;
						};

						vgen5 {
							regulator-min-microvolt = <0x1b7740>;
							regulator-max-microvolt = <0x325aa0>;
							regulator-always-on;
						};

						vgen6 {
							regulator-min-microvolt = <0x1b7740>;
							regulator-max-microvolt = <0x325aa0>;
							regulator-always-on;
						};
					};
				};
			};

			i2c@021a8000 {
				#address-cells = <0x1>;
				#size-cells = <0x0>;
				compatible = "fsl,imx6q-i2c", "fsl,imx21-i2c";
				reg = <0x21a8000 0x4000>;
				interrupts = <0x0 0x26 0x4>;
				clocks = <0x2 0x7f>;
				status = "okay";
				clock-frequency = <0x186a0>;
				pinctrl-names = "default";
				pinctrl-0 = <0x28>;

				rtc@30 {
					compatible = "rx8025";
					reg = <0x32>;
				};
			};

			romcp@021ac000 {
				reg = <0x21ac000 0x4000>;
			};

			mmdc0-1@021b0000 {
				compatible = "fsl,imx6q-mmdc-combine";
				reg = <0x21b0000 0x8000>;
			};

			mmdc@021b0000 {
				compatible = "fsl,imx6q-mmdc";
				reg = <0x21b0000 0x4000>;
			};

			mmdc@021b4000 {
				reg = <0x21b4000 0x4000>;
			};

			weim@021b8000 {
				compatible = "fsl,imx6q-weim";
				reg = <0x21b8000 0x4000>;
				interrupts = <0x0 0xe 0x4>;
				clocks = <0x2 0xc4>;
			};

			ocotp-ctrl@021bc000 {
				compatible = "syscon";
				reg = <0x21bc000 0x4000>;
				clocks = <0x2 0x80>;
				linux,phandle = <0x10>;
				phandle = <0x10>;
			};

			ocotp-fuse@021bc000 {
				compatible = "fsl,imx6q-ocotp";
				reg = <0x21bc000 0x4000>;
				clocks = <0x2 0x80>;
			};

			tzasc@021d0000 {
				reg = <0x21d0000 0x4000>;
				interrupts = <0x0 0x6c 0x4>;
			};

			tzasc@021d4000 {
				reg = <0x21d4000 0x4000>;
				interrupts = <0x0 0x6d 0x4>;
			};

			audmux@021d8000 {
				compatible = "fsl,imx6q-audmux", "fsl,imx31-audmux";
				reg = <0x21d8000 0x4000>;
				status = "okay";
				pinctrl-names = "default";
				pinctrl-0 = <0x29>;
			};

			mipi_csi@021dc000 {
				compatible = "fsl,imx6q-mipi-csi2";
				reg = <0x21dc000 0x4000>;
				interrupts = <0x0 0x64 0x4 0x0 0x65 0x4>;
				clocks = <0x2 0x8a 0x2 0x35 0x2 0xd5>;
				clock-names = "dphy_clk", "pixel_clk", "cfg_clk";
				status = "disabled";
				ipu_id = <0x0>;
				csi_id = <0x1>;
				v_channel = <0x0>;
				lanes = <0x2>;
			};

			mipi@021e0000 {
				reg = <0x21e0000 0x4000>;
				compatible = "fsl,imx6q-mipi-dsi";
				interrupts = <0x0 0x66 0x4>;
				gpr = <0xe>;
				clocks = <0x2 0x8a 0x2 0xd5>;
				clock-names = "mipi_pllref_clk", "mipi_cfg_clk";
				status = "disabled";
				ipu_id = <0x1>;
				dev_id = <0x0>;
				disp_id = <0x0>;
				lcd_panel = "TRULY-WVGA";
				disp-power-on-supply = <0x2a>;
				resets = <0x2b>;
			};

			vdoa@021e4000 {
				compatible = "fsl,imx6q-vdoa";
				reg = <0x21e4000 0x4000>;
				interrupts = <0x0 0x12 0x4>;
				clocks = <0x2 0xca>;
				iram = <0xa>;
			};

			serial@021e8000 {
				compatible = "fsl,imx6q-uart", "fsl,imx21-uart";
				reg = <0x21e8000 0x4000>;
				interrupts = <0x0 0x1b 0x4>;
				clocks = <0x2 0xa0 0x2 0xa1>;
				clock-names = "ipg", "per";
				dmas = <0x5 0x1b 0x4 0x0 0x5 0x1c 0x4 0x0>;
				dma-names = "rx", "tx";
				status = "okay";
				pinctrl-names = "default";
				pinctrl-0 = <0x2c>;
			};

			serial@021ec000 {
				compatible = "fsl,imx6q-uart", "fsl,imx21-uart";
				reg = <0x21ec000 0x4000>;
				interrupts = <0x0 0x1c 0x4>;
				clocks = <0x2 0xa0 0x2 0xa1>;
				clock-names = "ipg", "per";
				dmas = <0x5 0x1d 0x4 0x0 0x5 0x1e 0x4 0x0>;
				dma-names = "rx", "tx";
				status = "okay";
				pinctrl-names = "default";
				pinctrl-0 = <0x2d>;
			};

			serial@021f0000 {
				compatible = "fsl,imx6q-uart", "fsl,imx21-uart";
				reg = <0x21f0000 0x4000>;
				interrupts = <0x0 0x1d 0x4>;
				clocks = <0x2 0xa0 0x2 0xa1>;
				clock-names = "ipg", "per";
				dmas = <0x5 0x1f 0x4 0x0 0x5 0x20 0x4 0x0>;
				dma-names = "rx", "tx";
				status = "okay";
				pinctrl-names = "default";
				pinctrl-0 = <0x2e>;
			};

			serial@021f4000 {
				compatible = "fsl,imx6q-uart", "fsl,imx21-uart";
				reg = <0x21f4000 0x4000>;
				interrupts = <0x0 0x1e 0x4>;
				clocks = <0x2 0xa0 0x2 0xa1>;
				clock-names = "ipg", "per";
				dmas = <0x5 0x21 0x4 0x0 0x5 0x22 0x4 0x0>;
				dma-names = "rx", "tx";
				status = "okay";
				pinctrl-names = "default";
				pinctrl-0 = <0x2f>;
			};
		};

		ipu@02400000 {
			compatible = "fsl,imx6q-ipu";
			reg = <0x2400000 0x400000>;
			interrupts = <0x0 0x6 0x4 0x0 0x5 0x4>;
			clocks = <0x2 0x82 0x2 0x83 0x2 0x84 0x2 0x27 0x2 0x28 0x2 0x87 0x2 0x88>;
			clock-names = "bus", "di0", "di1", "di0_sel", "di1_sel", "ldb_di0", "ldb_di1";
			resets = <0xb 0x2>;
			bypass_reset = <0x0>;
		};

		imx_ion {
			compatible = "fsl,mxc-ion";
			fsl,heap-id = <0x0>;
		};

		busfreq {
			compatible = "fsl,imx_busfreq";
			clocks = <0x2 0xab 0x2 0x6 0x2 0xb 0x2 0x68 0x2 0xac 0x2 0x3a 0x2 0x12 0x2 0x3c 0x2 0x14 0x2 0x3>;
			clock-names = "pll2_bus", "pll2_pfd2_396m", "pll2_198m", "arm", "pll3_usb_otg", "periph", "periph_pre", "periph_clk2", "periph_clk2_sel", "osc";
			interrupts = <0x0 0x6b 0x4 0x0 0x70 0x4 0x0 0x71 0x4 0x0 0x72 0x4>;
			interrupt-names = "irq_busfreq_0", "irq_busfreq_1", "irq_busfreq_2", "irq_busfreq_3";
			fsl,max_ddr_freq = <0x1f78a400>;
		};

		gpu@00130000 {
			compatible = "fsl,imx6q-gpu";
			reg = <0x130000 0x4000 0x134000 0x4000 0x2204000 0x4000 0x0 0x0>;
			reg-names = "iobase_3d", "iobase_2d", "iobase_vg", "phys_baseaddr";
			interrupts = <0x0 0x9 0x4 0x0 0xa 0x4 0x0 0xb 0x4>;
			interrupt-names = "irq_3d", "irq_2d", "irq_vg";
			clocks = <0x2 0x1a 0x2 0x8f 0x2 0x1b 0x2 0x79 0x2 0x7a 0x2 0x4a>;
			clock-names = "gpu2d_axi_clk", "openvg_axi_clk", "gpu3d_axi_clk", "gpu2d_clk", "gpu3d_clk", "gpu3d_shader_clk";
			resets = <0xb 0x0 0xb 0x3 0xb 0x3>;
			reset-names = "gpu3d", "gpu2d", "gpuvg";
			power-domains = <0xc 0x1>;
		};

		sram@00900000 {
			compatible = "fsl,lpm-sram";
			reg = <0x900000 0x4000>;
			clocks = <0x2 0x8e>;
		};

		sram@00904000 {
			compatible = "fsl,ddr-lpm-sram";
			reg = <0x904000 0x1000>;
			clocks = <0x2 0x8e>;
		};

		sram@00905000 {
			compatible = "mmio-sram";
			reg = <0x905000 0x3b000>;
			clocks = <0x2 0x8e>;
			linux,phandle = <0xa>;
			phandle = <0xa>;
		};

		sata@02200000 {
			compatible = "fsl,imx6q-ahci";
			reg = <0x2200000 0x4000>;
			interrupts = <0x0 0x27 0x4>;
			clocks = <0x2 0x9a 0x2 0xbb 0x2 0x69>;
			clock-names = "sata", "sata_ref", "ahb";
			status = "okay";
		};

		ipu@02800000 {
			compatible = "fsl,imx6q-ipu";
			reg = <0x2800000 0x400000>;
			interrupts = <0x0 0x8 0x4 0x0 0x7 0x4>;
			clocks = <0x2 0x85 0x2 0x86 0x2 0x89 0x2 0x29 0x2 0x2a 0x2 0x87 0x2 0x88>;
			clock-names = "bus", "di0", "di1", "di0_sel", "di1_sel", "ldb_di0", "ldb_di1";
			resets = <0xb 0x4>;
			bypass_reset = <0x0>;
		};
	};

	cpus {
		#address-cells = <0x1>;
		#size-cells = <0x0>;

		cpu@0 {
			compatible = "arm,cortex-a9";
			device_type = "cpu";
			reg = <0x0>;
			next-level-cache = <0x30>;
			operating-points = <0x124f80 0x137478 0xf32a0 0x1312d0 0xd0020 0x1312d0 0xc15c0 0x11edd8 0x60ae0 0xee098>;
			fsl,soc-operating-points = <0x124f80 0x137478 0xf32a0 0x1312d0 0xd0020 0x1312d0 0xc15c0 0x11edd8 0x60ae0 0x11edd8>;
			clock-latency = <0xee6c>;
			clocks = <0x2 0x68 0x2 0x6 0x2 0x10 0x2 0x11 0x2 0xaa 0x2 0xee 0x2 0xe7 0x2 0xe0>;
			clock-names = "arm", "pll2_pfd2_396m", "step", "pll1_sw", "pll1_sys", "pll1_bypass", "pll1", "pll1_bypass_src";
			arm-supply = <0x31>;
			pu-supply = <0x12>;
			soc-supply = <0x32>;
		};

		cpu@1 {
			compatible = "arm,cortex-a9";
			device_type = "cpu";
			reg = <0x1>;
			next-level-cache = <0x30>;
		};

		cpu@2 {
			compatible = "arm,cortex-a9";
			device_type = "cpu";
			reg = <0x2>;
			next-level-cache = <0x30>;
		};

		cpu@3 {
			compatible = "arm,cortex-a9";
			device_type = "cpu";
			reg = <0x3>;
			next-level-cache = <0x30>;
		};
	};

	max8903@0 {
		compatible = "fsl,max8903-charger";
		pinctrl-names = "default";
		dok_input = <0x22 0x18 0x1>;
		chg_input = <0x27 0x17 0x1>;
		flt_input = <0x1f 0x2 0x1>;
		fsl,dcm_always_high;
		fsl,dc_valid;
		fsl,usb_valid;
		status = "okay";
		offset-charger = <0x76c>;
		offset-discharger = <0x69e>;
		offset-usb-charger = <0x695>;
	};

	hannstar_cabc {
		compatible = "hannstar,cabc";

		lvds0 {
			gpios = <0x33 0xf 0x0>;
		};

		lvds1 {
			gpios = <0x4 0xc 0x0>;
		};
	};

	leds {
		compatible = "gpio-leds";

		charger-led {
			gpios = <0x34 0x2 0x0>;
			linux,default-trigger = "max8903-charger-charging";
			retain-state-suspended;
		};

		wifi-led {
			gpios = <0x1f 0xb 0x0>;
			linux,default-trigger = "max8903-charger-charging";
			retain-state-suspended;
		};

		4g-led0 {
			gpios = <0x4 0x4 0x1>;
			linux,default-trigger = "max8903-charger-charging";
			retain-state-suspended;
		};
	};

	regulators {
		compatible = "simple-bus";
		#address-cells = <0x1>;
		#size-cells = <0x0>;

		regulator@0 {
			compatible = "regulator-fixed";
			reg = <0x0>;
			regulator-name = "usb_otg_vbus";
			regulator-min-microvolt = <0x4c4b40>;
			regulator-max-microvolt = <0x4c4b40>;
			gpio = <0x27 0x16 0x0>;
			enable-active-high;
			linux,phandle = <0x18>;
			phandle = <0x18>;
		};

		regulator@1 {
			compatible = "regulator-fixed";
			reg = <0x1>;
			regulator-name = "usb_h1_vbus";
			regulator-min-microvolt = <0x4c4b40>;
			regulator-max-microvolt = <0x4c4b40>;
			enable-active-high;
			linux,phandle = <0x1b>;
			phandle = <0x1b>;
		};

		regulator@2 {
			compatible = "regulator-fixed";
			reg = <0x2>;
			regulator-name = "wm8960-supply";
			enable-active-high;
			linux,phandle = <0x25>;
			phandle = <0x25>;
		};

		mipi_dsi_pwr_on {
			compatible = "regulator-fixed";
			regulator-name = "mipi_dsi_pwr_on";
			gpio = <0x33 0xe 0x0>;
			enable-active-high;
			linux,phandle = <0x2a>;
			phandle = <0x2a>;
		};

		regulator@3 {
			compatible = "regulator-fixed";
			reg = <0x3>;
			regulator-name = "sensor-supply";
			regulator-min-microvolt = <0x325aa0>;
			regulator-max-microvolt = <0x325aa0>;
			gpio = <0x22 0x1f 0x0>;
			startup-delay-us = <0x1f4>;
			enable-active-high;
		};
	};

	gpio-keys {
		compatible = "gpio-keys";
		pinctrl-names = "default";
		pinctrl-0 = <0x35>;

		power {
			label = "Power Button";
			gpios = <0x4 0x7 0x1>;
			gpio-key,wakeup;
			linux,code = <0x74>;
		};

		back-key {
			label = "Back Key";
			gpios = <0x4 0x8 0x1>;
			gpio-key,wakeup;
			linux,code = <0x9e>;
		};

		volume-up {
			label = "Volume Up";
			gpios = <0x34 0x4 0x1>;
			gpio-key,wakeup;
			linux,code = <0x73>;
		};

		volume-down {
			label = "Volume Down";
			gpios = <0x34 0x5 0x1>;
			gpio-key,wakeup;
			linux,code = <0x72>;
		};
	};

	sound {
		compatible = "fsl,imx6q-sabresd-wm8960", "fsl,imx-audio-wm8960";
		model = "wm8960-audio";
		cpu-dai = <0x36>;
		audio-codec = <0x37>;
		codec-master;
		hp-det = <0x3 0x0>;
		audio-routing = "Headphone Jack", "HP_L", "Headphone Jack", "HP_R", "Ext Spk", "SPK_LP", "Ext Spk", "SPK_RP", "LINPUT1", "MICB", "MICB", "AMIC";
		mux-int-port = <0x2>;
		mux-ext-port = <0x4>;
	};

	sound-hdmi {
		compatible = "fsl,imx6q-audio-hdmi", "fsl,imx-audio-hdmi";
		model = "imx-audio-hdmi";
		hdmi-controller = <0x38>;
	};

	fb@0 {
		compatible = "fsl,mxc_sdc_fb";
		disp_dev = "ldb";
		interface_pix_fmt = "RGB24";
		default_bpp = <0x20>;
		int_clk = <0x0>;
		late_init = <0x0>;
		status = "okay";
	};

	fb@1 {
		compatible = "fsl,mxc_sdc_fb";
		disp_dev = "hdmi";
		interface_pix_fmt = "RGB24";
		mode_str = "1920x1080M@60";
		default_bpp = <0x20>;
		int_clk = <0x0>;
		late_init = <0x0>;
		status = "okay";
	};

	fb@2 {
		compatible = "fsl,mxc_sdc_fb";
		disp_dev = "ldb";
		interface_pix_fmt = "RGB24";
		default_bpp = <0x20>;
		int_clk = <0x0>;
		late_init = <0x0>;
		status = "okay";
	};

	fb@3 {
		compatible = "fsl,mxc_sdc_fb";
		disp_dev = "lcd";
		interface_pix_fmt = "RGB24";
		mode_str = "TM070RDH13";
		default_bpp = <0x20>;
		int_clk = <0x1>;
		late_init = <0x0>;
		status = "okay";
	};

	lcd@0 {
		compatible = "fsl,lcd";
		ipu_id = <0x0>;
		disp_id = <0x0>;
		default_ifmt = "RGB666";
		pinctrl-names = "default";
		pinctrl-0 = <0x39>;
		status = "okay";
	};

	backlight {
		compatible = "pwm-backlight";
		pwms = <0x3a 0x0 0x4c4b40>;
		brightness-levels = <0x0 0x4 0x8 0x10 0x20 0x40 0x80 0xff>;
		default-brightness-level = <0x7>;
		status = "okay";
	};

	v4l2_cap_0 {
		compatible = "fsl,imx6q-v4l2-capture";
		ipu_id = <0x0>;
		csi_id = <0x0>;
		mclk_source = <0x0>;
		status = "okay";
	};

	v4l2_cap_1 {
		compatible = "fsl,imx6q-v4l2-capture";
		ipu_id = <0x0>;
		csi_id = <0x1>;
		mclk_source = <0x0>;
		status = "okay";
	};

	v4l2_out {
		compatible = "fsl,mxc_v4l2_output";
		status = "okay";
	};

	mipi-dsi-reset {
		compatible = "gpio-reset";
		reset-gpios = <0x4 0x4 0x0>;
		reset-delay-us = <0x7a120>;
		#reset-cells = <0x0>;
		linux,phandle = <0x2b>;
		phandle = <0x2b>;
	};
};
